# Template register map
Vendor: VendorName Co.Ltd; Series: SeriesName; File version: 1.2
CPU: CM7 r0p1, little endian, MPU, FPU, 4 interrupt priority bits
Registers are 32-bit, read-write, no defined reset value unless marked. A register's access mark holds for its fields unless they carry their own. Offsets are from the block's base; [hi:lo] are bit positions.

## QSPI — Quad Serial Peripheral Interface
Base 0x84000000
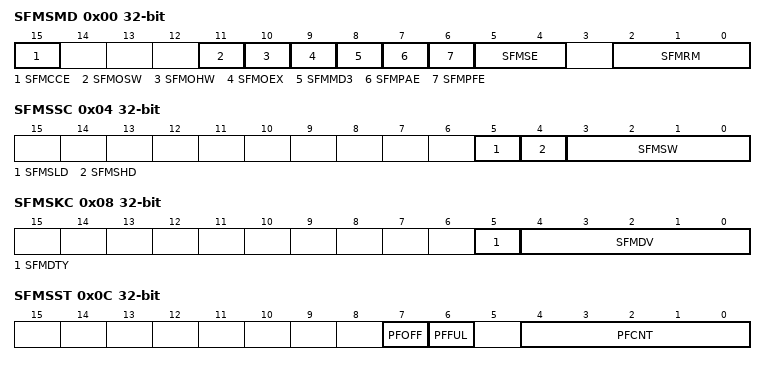
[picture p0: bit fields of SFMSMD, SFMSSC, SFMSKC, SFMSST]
0x00 SFMSMD — QSPI transfer mode control register
  [15] SFMCCE — QSPI SFMCCE bit: read instruction code select
  [11] SFMOSW — QSPI SFMOSW bit: setup time adjustment for serial transmission
  [10] SFMOHW — QSPI SFMOHW bit: hold time adjustment for serial transmission
  [9] SFMOEX — QSPI SFMOEX bit: extension select for I/O buffer output enable signal
  [8] SFMMD3 — QSPI SFMMD3 bit: SPI mode select
  [7] SFMPAE — QSPI SFMPAE bit: function select for stopping prefetch at locations
  [6] SFMPFE — QSPI SFMPFE bit: prefetch function select
  [5:4] SFMSE — QSPI SFMSE[1:0] bit: QSSL extension function select after SPI bus access
  [2:0] SFMRM — QSPI SFMRM[2:0] bit: serial interface read mode select
0x04 SFMSSC — QSPI chip selection control register
  [5] SFMSLD — QSPI SFMSLD bit: QSSL signal output timing select
  [4] SFMSHD — QSPI SFMSHD bit: QSSL signal release timing select
  [3:0] SFMSW — QSPI SFMSW[3:0] bit: minimum high-level width select for QSSL signal
0x08 SFMSKC — QSPI clock control register
  [5] SFMDTY — QSPI SFMDTY bit: duty ratio correction function select for the QSPCLK signal
  [4:0] SFMDV — QSPI SFMDV[4:0] bit: serial interface reference cycle select
0x0C SFMSST ro — QSPI status register
  [7] PFOFF — QSPI PFOFF bit: prefetch function operating state
  [6] PFFUL — QSPI PFFUL bit: prefetch buffer state
  [4:0] PFCNT — QSPI PFCNT[4:0] bit: number of bytes of prefetched data
0x10 SFMCOM — QSPI communication port register
  [7:0] SFMD — QSPI SFMD[7:0] bit: port for direct communication with the SPI bus
0x14 SFMCMD — QSPI communication mode control register
  [0] DCOM — QSPI DCOM bit: mode select for communication with the SPI bus
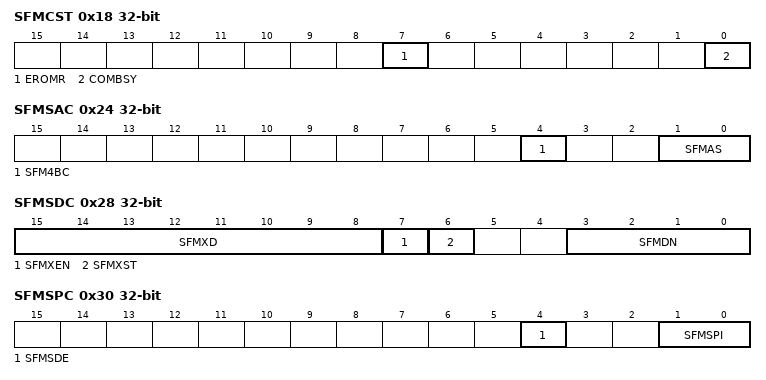
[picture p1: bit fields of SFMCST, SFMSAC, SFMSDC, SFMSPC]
0x18 SFMCST — QSPI communication status register
  [7] EROMR — QSPI EROMR bit: ROM access detection status in direct communication mode
  [0] COMBSY ro — QSPI COMBSY bit: SPI bus cycle completion state in direct communication
0x20 SFMSIC — QSPI instruction code register
  [7:0] SFMCIC — QSPI SFMCIC[7:0] bit: serial flash instruction code to substitute
0x24 SFMSAC — QSPI address mode control register
  [4] SFM4BC — QSPI SFM4BC bit: default instruction code select when serial interface address width is 4 bytes
  [1:0] SFMAS — QSPI SFMAS[1:0] bit: number of address bytes select for the serial interface
0x28 SFMSDC — QSPI dummy cycle control register
  [15:8] SFMXD — QSPI SFMXD[7:0] bit: mode data for serial flash
  [7] SFMXEN — QSPI SFMXEN bit: XIP mode permission in the QSPI
  [6] SFMXST ro — QSPI SFMXST bit: XIP mode status
  [3:0] SFMDN — QSPI SFMDN[3:0] bit: number of dummy cycles select for fast read instructions
0x30 SFMSPC — QSPI SPI protocol control register
  [4] SFMSDE — QSPI SFMSDE bit: minimum time select for input or output switch
  [1:0] SFMSPI — QSPI SFMSPI[1:0] bit: SPI protocol select
0x34 SFMPMD — QSPI port control register
  [2] SFMWPL — QSPI SFMWPL bit: WP pin level specification
0x804 SFMCNT1 — QSPI external QSPI address register
  [31:26] QSPIEXIT — QSPI QSPIEXIT[5:0] bit: bank switching address

## SEMA — Semaphores
Base 0x40090000
0x00 GATE3 8-bit — SEMA semaphore gate 3 register
  [3:0] GTFSM — SEMA GTFSM[3:0] bit: gate 3 finite state machine
0x01 GATE2 8-bit — SEMA semaphore gate 2 register
  [3:0] GTFSM — SEMA GTFSM[3:0] bit: gate 2 finite state machine
0x02 GATE1 8-bit — SEMA semaphore gate 1 register
  [3:0] GTFSM — SEMA GTFSM[3:0] bit: gate 1 finite state machine
0x03 GATE0 8-bit — SEMA semaphore gate 0 register
  [3:0] GTFSM — SEMA GTFSM[3:0] bit: gate 0 finite state machine
0x04 GATE7 8-bit — SEMA semaphore gate 7 register
  [3:0] GTFSM — SEMA GTFSM[3:0] bit: gate 7 finite state machine
0x05 GATE6 8-bit — SEMA semaphore gate 6 register
  [3:0] GTFSM — SEMA GTFSM[3:0] bit: gate 6 finite state machine
0x06 GATE5 8-bit — SEMA semaphore gate 5 register
  [3:0] GTFSM — SEMA GTFSM[3:0] bit: gate 5 finite state machine
0x07 GATE4 8-bit — SEMA semaphore gate 4 register
  [3:0] GTFSM — SEMA GTFSM[3:0] bit: gate 4 finite state machine
0x08 GATE11 8-bit — SEMA semaphore gate 11 register
  [3:0] GTFSM — SEMA GTFSM[3:0] bit: gate 11 finite state machine
0x09 GATE10 8-bit — SEMA semaphore gate 10 register
  [3:0] GTFSM — SEMA GTFSM[3:0] bit: gate 10 finite state machine
0x0A GATE9 8-bit — SEMA semaphore gate 9 register
  [3:0] GTFSM — SEMA GTFSM[3:0] bit: gate 9 finite state machine
0x0B GATE8 8-bit — SEMA semaphore gate 8 register
  [3:0] GTFSM — SEMA GTFSM[3:0] bit: gate 8 finite state machine
0x0C GATE15 8-bit — SEMA semaphore gate 15 register
  [3:0] GTFSM — SEMA GTFSM[3:0] bit: gate 15 finite state machine
0x0D GATE14 8-bit — SEMA semaphore gate 14 register
  [3:0] GTFSM — SEMA GTFSM[3:0] bit: gate 14 finite state machine
0x0E GATE13 8-bit — SEMA semaphore gate 13 register
  [3:0] GTFSM — SEMA GTFSM[3:0] bit: gate 13 finite state machine
0x0F GATE12 8-bit — SEMA semaphore gate 12 register
  [3:0] GTFSM — SEMA GTFSM[3:0] bit: gate 12 finite state machine
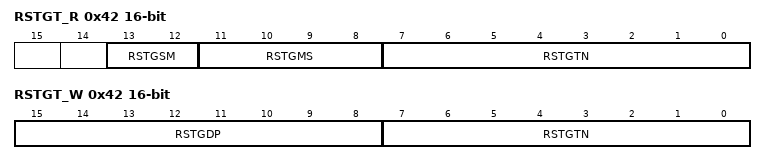
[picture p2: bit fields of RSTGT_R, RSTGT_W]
0x42 RSTGT_R 16-bit ro — SEMA reset gate read register
  [13:12] RSTGSM — SEMA RSTGSM[1:0] bit: reset gate finite state machine
  [11:8] RSTGMS — SEMA RSTGMS[3:0] bit: reset gate bus master
  [7:0] RSTGTN — SEMA RSTGTN[7:0] bit: reset gate number
0x42 RSTGT_W 16-bit wo — SEMA reset gate read register
  [15:8] RSTGDP — SEMA RSTGDP[7:0] bit: reset gate data pattern
  [7:0] RSTGTN — SEMA RSTGTN[7:0] bit: reset gate number

## STIM1 — System Timer 1
Base 0x400C5000
Same registers: STIM2 0x400C6000, STIM3 0x400C7000
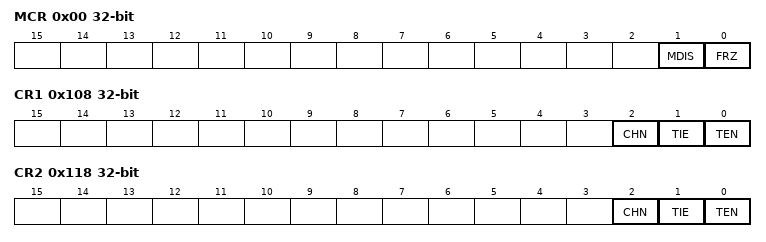
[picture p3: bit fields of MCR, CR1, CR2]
0x00 MCR — STIM module control register
  [1] MDIS — STIM MDIS bit: STIM module enable control
  [0] FRZ — STIM FRZ bit: STIM freeze function enable control under emulation mode
0xE0 CNT64H ro — STIM 64 bits timer higher value register
  [31:0] LTH — STIM LTH[31:0] bit: high 32 bits vlaue of 64 bits timer
0xE4 CNT64L ro — STIM 64 bits timer lower value register
  [31:0] LTL — STIM LTL[31:0] bit: low 32 bits vlaue of 64 bits timer
0x100 ARR1 — STIM timer load value register 1
  [31:0] TSV — STIM TSV[31:0] bit: timer start value of register 1
0x104 CNT1 ro — STIM current timer value register 1
  [31:0] TVL — STIM TVL[31:0] bit: current timer value of register 1
0x108 CR1 — STIM timer control register 1
  [2] CHN — STIM CHN bit: timer cascade mode of register 1
  [1] TIE — STIM TIE bit: timer interruption enable of register 1
  [0] TEN — STIM TEN bit: timer enable of register 1
0x10C SR1 — STIM timer flag register 1
  [0] TIF — STIM TIF bit: timer interrupt flag of register 1
0x110 ARR2 — STIM timer load value register 2
  [31:0] TSV — STIM TSV[31:0] bit: timer start value of register 2
0x114 CNT2 ro — STIM current timer value register 2
  [31:0] TVL — STIM TVL[31:0] bit: current timer value of register 2
0x118 CR2 — STIM timer control register 2
  [2] CHN — STIM CHN bit: timer cascade enable of register 2
  [1] TIE — STIM TIE bit: timer interruption enable of register 2
  [0] TEN — STIM TEN bit: timer enable of register 2
0x11C SR2 — STIM timer flag register 2
  [0] TIF — STIM TIF bit: timer interrupt flag of register 2

## WWDG — System window watchdog
Base 0x400C2000
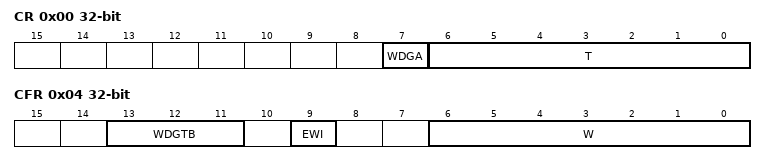
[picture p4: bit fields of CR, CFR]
0x00 CR — WWDG control register
  [7] WDGA — WWDG WDGA bit: WWDG counter enable bit
  [6:0] T — WWDG T[6:0] bit: 7-bit counter
0x04 CFR — WWDG configuration register
  [13:11] WDGTB — WWDG WDGTB[2:0] bit: clock frequency division number
  [9] EWI — WWDG EWI bit: early wakeup interrupt
  [6:0] W — WWDG W[6:0] bit: 7-bit window value
0x08 SR — WWDG status register
  [0] EWIF — WWDG EWIF bit: early wakeup interrupt flag
